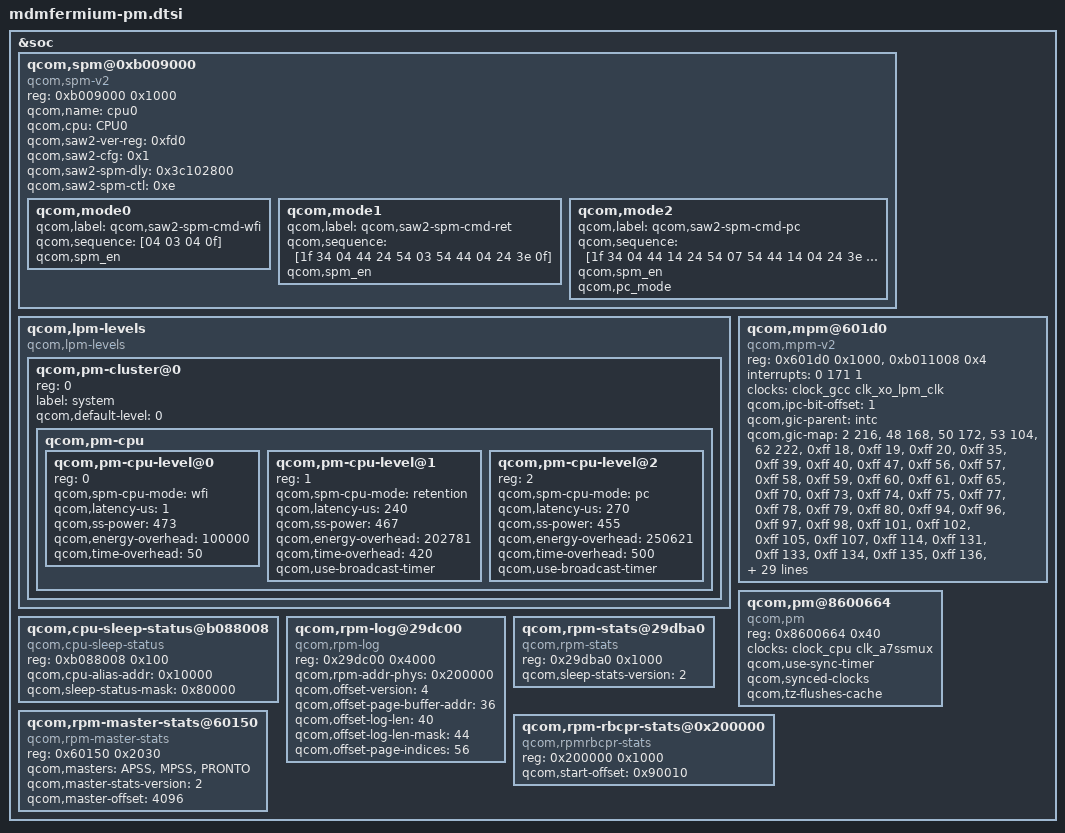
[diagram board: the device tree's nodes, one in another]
/* Copyright (c) 2015, The Linux Foundation. All rights reserved.
 *
 * This program is free software; you can redistribute it and/or modify
 * it under the terms of the GNU General Public License version 2 and
 * only version 2 as published by the Free Software Foundation.
 *
 * This program is distributed in the hope that it will be useful,
 * but WITHOUT ANY WARRANTY; without even the implied warranty of
 * MERCHANTABILITY or FITNESS FOR A PARTICULAR PURPOSE.  See the
 * GNU General Public License for more details.
 */

&soc {
	qcom,spm@0xb009000 {
		compatible = "qcom,spm-v2";
		#address-cells = <1>;
		#size-cells = <1>;
		reg = <0xb009000 0x1000>;
		qcom,name = "cpu0";
		qcom,cpu = <&CPU0>;
		qcom,saw2-ver-reg = <0xfd0>;
		qcom,saw2-cfg = <0x1>;
		qcom,saw2-spm-dly= <0x3c102800>;
		qcom,saw2-spm-ctl = <0xe>;
		qcom,mode0 {
			qcom,label = "qcom,saw2-spm-cmd-wfi";
			qcom,sequence = [04 03 04 0f];
			qcom,spm_en;
		};

		qcom,mode1 {
			qcom,label = "qcom,saw2-spm-cmd-ret";
			qcom,sequence = [1f 34 04 44 24 54 03
				54 44 04 24 3e 0f];
			qcom,spm_en;
		};

		qcom,mode2 {
			qcom,label = "qcom,saw2-spm-cmd-pc";
			qcom,sequence = [1f 34 04 44 14 24 54 07
				54 44 14 04 24 3e 0f];
			qcom,spm_en;
			qcom,pc_mode;
		};
	};

	qcom,lpm-levels {
		compatible = "qcom,lpm-levels";
		#address-cells = <1>;
		#size-cells = <0>;

		qcom,pm-cluster@0{
			#address-cells = <1>;
			#size-cells = <0>;
			reg = <0>;
			label = "system";
			qcom,default-level=<0>;

			qcom,pm-cpu {
				#address-cells = <1>;
				#size-cells = <0>;

				qcom,pm-cpu-level@0{
					reg = <0>;
					qcom,spm-cpu-mode = "wfi";
					qcom,latency-us = <1>;
					qcom,ss-power = <473>;
					qcom,energy-overhead = <100000>;
					qcom,time-overhead = <50>;
				};

				qcom,pm-cpu-level@1 {
					reg = <1>;
					qcom,spm-cpu-mode ="retention";
					qcom,latency-us = <240>;
					qcom,ss-power = <467>;
					qcom,energy-overhead = <202781>;
					qcom,time-overhead = <420>;
					qcom,use-broadcast-timer;
				};

				qcom,pm-cpu-level@2 {
					reg = <2>;
					qcom,spm-cpu-mode = "pc";
					qcom,latency-us = <270>;
					qcom,ss-power = <455>;
					qcom,energy-overhead = <250621>;
					qcom,time-overhead = <500>;
					qcom,use-broadcast-timer;
				};
			};
		};
	};

	qcom,mpm@601d0 {
		compatible = "qcom,mpm-v2";
		reg = <0x601d0 0x1000>, /* MSM_RPM_MPM_BASE 4K */
		    <0xb011008 0x4>;
		reg-names = "vmpm", "ipc";
		interrupts = <0 171 1>;
		clocks = <&clock_gcc clk_xo_lpm_clk>;
		clock-names = "xo";
		qcom,ipc-bit-offset = <1>;
		qcom,gic-parent = <&intc>;
		qcom,gic-map = <2 216>, /* tsens_upper_lower_int */
			<48 168>, /* usb_phy_id_irq */
			<50 172>, /* usb1_hs_async_wakeup_irq */
			<53 104>, /* mdss_irq */
			<62 222>, /* ee0_krait_hlos_spmi_periph_irq */
			<0xff 18>,  /* APC_qgicQTmrSecPhysIrptReq */
			<0xff 19>,  /* APC_qgicQTmrNonSecPhysIrptReq */
			<0xff 20>,  /* qgicQTmrVirtIrptReq */
			<0xff 35>,  /* WDT_barkInt */
			<0xff 39>,  /* arch_mem_timer */
			<0xff 40>,  /* qtmr_phy_irq[0] */
			<0xff 47>,  /* rbif_irq[0] */
			<0xff 56>,  /* q6_wdog_expired_irq */
			<0xff 57>,  /* mss_to_apps_irq(0) */
			<0xff 58>,  /* mss_to_apps_irq(1) */
			<0xff 59>,  /* mss_to_apps_irq(2) */
			<0xff 60>,  /* mss_to_apps_irq(3) */
			<0xff 61>,  /* mss_a2_bam_irq */
			<0xff 65>,  /* o_gc_sys_irq[0] */
			<0xff 70>,  /* smmu_bus_intr[0] */
			<0xff 73>,  /* smmu_bus_intr[1] */
			<0xff 74>,  /* smmu_bus_intr[2] */
			<0xff 75>,  /* smmu_bus_intr[3] */
			<0xff 77>,  /* smmu_bus_intr[4] */
			<0xff 78>,  /* smmu_bus_intr[5] */
			<0xff 79>,  /* smmu_bus_intr[6] */
			<0xff 80>,  /* smmu_bus_intr[7] */
			<0xff 94>,  /* smmu_bus_intr[8] */
			<0xff 96>,  /* smmu_bus_intr[9] */
			<0xff 97>,  /* smmu_bus_intr[10] */
			<0xff 98>,  /* smmu_bus_intr[11] */
			<0xff 101>, /* smmu_bus_intr[13] */
			<0xff 102>, /* smmu_bus_intr[14] */
			<0xff 105>, /* msm_iommu_global_cfg_irq */
			<0xff 107>, /* msm_iommu_global_cfg_irq */
			<0xff 114>, /* qdsd_intr_out */
			<0xff 131>, /* qup_irq */
			<0xff 133>, /* smmu_bus_intr[29] */
			<0xff 134>, /* smmu_bus_intr[30] */
			<0xff 135>, /* smmu_bus_intr[31] */
			<0xff 136>, /* smmu_bus_intr[32] */
			<0xff 137>, /* smmu_bus_intr[33] */
			<0xff 138>, /* smmu_bus_intr[34] */
			<0xff 140>, /* uart_dm_intr */
			<0xff 141>, /* smmu_bus_intr[35] */
			<0xff 142>, /* smmu_bus_intr[36] */
			<0xff 143>, /* smmu_bus_intr[37] */
			<0xff 144>, /* smmu_bus_intr[38] */
			<0xff 145>, /* smmu_bus_intr[39] */
			<0xff 146>, /* smmu_bus_intr[40] */
			<0xff 147>, /* smmu_bus_intr[41] */
			<0xff 148>, /* smmu_bus_intr[42] */
			<0xff 149>, /* smmu_bus_intr[43] */
			<0xff 150>, /* smmu_bus_intr[44] */
			<0xff 151>, /* smmu_bus_intr[45] */
			<0xff 152>, /* smmu_bus_intr[46] */
			<0xff 153>, /* smmu_bus_intr[47] */
			<0xff 154>, /* smmu_bus_intr[48] */
			<0xff 155>, /* sdc1_irq(0) */
			<0xff 157>, /* sdc2_irq(0) */
			<0xff 166>, /* usb_hs_irq */
			<0xff 170>, /* sdc1_pwr_cmd_irq */
			<0xff 173>, /* o_wcss_apss_smd_hi */
			<0xff 174>, /* o_wcss_apss_smd_med */
			<0xff 175>, /* o_wcss_apss_smd_low */
			<0xff 176>, /* o_wcss_apss_smsm_irq */
			<0xff 177>, /* o_wcss_apss_wlan_data_xfer_done */
			<0xff 178>, /* o_wcss_apss_wlan_rx_data_avail */
			<0xff 179>, /* o_wcss_apss_asic_intr */
			<0xff 181>, /* o_wcss_apss_wdog_bite_and_reset_rdy */
			<0xff 182>, /* smmu_bus_intr[58] */
			<0xff 183>, /* smmu_bus_intr[59] */
			<0xff 184>, /* smmu_bus_intr[60] */
			<0xff 188>, /* lpass_irq_out_apcs(0) */
			<0xff 189>, /* lpass_irq_out_apcs(1) */
			<0xff 190>, /* lpass_irq_out_apcs(2) */
			<0xff 191>, /* lpass_irq_out_apcs(3) */
			<0xff 192>, /* lpass_irq_out_apcs(4) */
			<0xff 193>, /* lpass_irq_out_apcs(5) */
			<0xff 194>, /* lpass_irq_out_apcs(6) */
			<0xff 195>, /* lpass_irq_out_apcs(7) */
			<0xff 196>, /* lpass_irq_out_apcs(8) */
			<0xff 197>, /* lpass_irq_out_apcs(9) */
			<0xff 198>, /* coresight-tmc-etr interrupt */
			<0xff 200>, /* rpm_ipc(4) */
			<0xff 201>, /* rpm_ipc(5) */
			<0xff 202>, /* rpm_ipc(6) */
			<0xff 203>, /* rpm_ipc(7) */
			<0xff 204>, /* rpm_ipc(24) */
			<0xff 205>, /* rpm_ipc(25) */
			<0xff 206>, /* rpm_ipc(26) */
			<0xff 207>, /* rpm_ipc(27) */
			<0xff 215>, /* o_bimc_intr */
			<0xff 224>, /* spdm_realtime_irq(1) */
			<0xff 239>, /* crypto_bam_irq[1]*/
			<0xff 240>, /* summary_irq_kpss */
			<0xff 253>, /* sdc2_pwr_cmd_irq */
			<0xff 255>, /* smmu_bus_intr[49] */
			<0xff 256>, /* smmu_bus_intr[50] */
			<0xff 257>, /* smmu_bus_intr[51] */
			<0xff 260>, /* smmu_bus_intr[52] */
			<0xff 261>, /* smmu_bus_intr[53] */
			<0xff 262>, /* smmu_bus_intr[54] */
			<0xff 263>, /* smmu_bus_intr[55] */
			<0xff 264>, /* smmu_bus_intr[56] */
			<0xff 265>, /* smmu_bus_intr[57] */
			<0xff 269>, /* rpm_wdog_expired_irq */
			<0xff 270>, /* blsp1_bam_irq[0] */
			<0xff 272>, /* smmu_bus_intr[17] */
			<0xff 273>, /* smmu_bus_intr[18] */
			<0xff 274>, /* smmu_bus_intr[19] */
			<0xff 275>, /* rpm_ipc(30) */
			<0xff 276>, /* rpm_ipc(31) */
			<0xff 277>, /* smmu_bus_intr[20] */
			<0xff 278>, /* smmu_bus_intr[21] */
			<0xff 279>, /* smmu_bus_intr[22] */
			<0xff 280>, /* smmu_bus_intr[23] */
			<0xff 281>, /* smmu_bus_intr[24] */
			<0xff 282>, /* smmu_bus_intr[25] */
			<0xff 283>, /* smmu_bus_intr[26] */
			<0xff 284>, /* smmu_bus_intr[27] */
			<0xff 285>; /* smmu_bus_intr[28] */

		qcom,gpio-parent = <&tlmm_pinmux>;
		qcom,gpio-map = <3  16>,
			<4  5>,
			<5  11>,
			<6  12>,
			<7  3>,
			<8  17>,
			<9  9>,
			<10  13>,
			<11  1>,
			<12  20>,
			<13  21>,
			<14  22>,
			<15  75>,
			<16  74>,
			<17  28>,
			<18  44>,
			<19  26>,
			<20  43>,
			<21  42>,
			<22  29>,
			<23  69>,
			<24  30>,
			<25  37>,
			<26  25>,
			<27  71>,
			<28  34>,
			<29  55>,
			<30  8>,
			<31  40>,
			<32  48>,
			<33  52>,
			<34  57>,
			<35  62>,
			<36  66>,
			<37  59>,
			<38  79>,
			<39  38>,
			<40  63>,
			<41  76>;
	};

	qcom,pm@8600664 {
		compatible = "qcom,pm";
		reg = <0x8600664 0x40>;
		clocks = <&clock_cpu  clk_a7ssmux>;
		clock-names = "cpu0_clk";
		qcom,use-sync-timer;
		qcom,synced-clocks;
		qcom,tz-flushes-cache;
	};

	qcom,cpu-sleep-status@b088008{
		compatible = "qcom,cpu-sleep-status";
		reg = <0xb088008 0x100>;
		qcom,cpu-alias-addr = <0x10000>;
		qcom,sleep-status-mask= <0x80000>;
	};

	qcom,rpm-log@29dc00 {
		compatible = "qcom,rpm-log";
		reg = <0x29dc00 0x4000>;
		qcom,rpm-addr-phys = <0x200000>;
		qcom,offset-version = <4>;
		qcom,offset-page-buffer-addr = <36>;
		qcom,offset-log-len = <40>;
		qcom,offset-log-len-mask = <44>;
		qcom,offset-page-indices = <56>;
	};

	qcom,rpm-stats@29dba0 {
		compatible = "qcom,rpm-stats";
		reg = <0x29dba0 0x1000>;
		reg-names = "phys_addr_base";
		qcom,sleep-stats-version = <2>;
	};

	qcom,rpm-master-stats@60150 {
		compatible = "qcom,rpm-master-stats";
		reg = <0x60150 0x2030>;
		qcom,masters = "APSS", "MPSS", "PRONTO";
		qcom,master-stats-version = <2>;
		qcom,master-offset = <4096>;
	};

	qcom,rpm-rbcpr-stats@0x200000  {
		compatible = "qcom,rpmrbcpr-stats";
		reg = <0x200000 0x1000>;
		qcom,start-offset = <0x90010>;
	};
};
